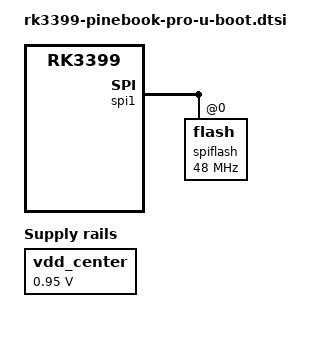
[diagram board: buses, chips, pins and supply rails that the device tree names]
// SPDX-License-Identifier: GPL-2.0+
/*
 * Copyright (C) 2019 Jagan Teki <jagan@amarulasolutions.com>
 */

#include "rk3399-u-boot.dtsi"
#include "rk3399-sdram-lpddr4-100.dtsi"
/ {
	chosen {
		u-boot,spl-boot-order = "same-as-spl", &spiflash, &sdmmc, &sdhci;
	};

	aliases {
		spi0 = &spi1;
	};
};

&spi1 {
	status = "okay";
	max-freq = <48000000>;

	spiflash: flash@0 {
		spi-max-frequency = <48000000>; 
		u-boot,dm-pre-reloc;
	};
};

&vdd_center {
	regulator-min-microvolt = <950000>;
	regulator-max-microvolt = <950000>;
};

&vdd_log {
	regulator-init-microvolt = <950000>;
};
